# CM85F register map
Registers are read-write, no defined reset value unless marked. A register's access mark holds for its fields unless they carry their own. Offsets are from the block's base; lines under a group give offsets from that group; [hi:lo] are bit positions; {n}, {i} and the like mark numbered series; 'fields as' and 'values as' point back to an identical list; <NAME> marks a mode.

## Memory map
0xE0005000 RAS_Ext size 0x9F08 — Reliability, Availability, and Serviceability (RAS) Extension
0xE000E004 ICB size 0xC — Implementation Control Block
0xE000E100 NVIC size 0xF00 — Nested Vectored Interrupt Controller
0xE000ECFC SCB size 0x90 — System Control Block
0xE000EF34 FP_MVE size 0x18 — Floating-point and MVE Extension
0xE001E000 MSC size 0x19D00 — Memory System Control Registers
0xE001E100 ERRBNK size 0x8 — Implementation defined error banking
0xE001E200 DCA size 0x10 — Direct Cache Access

## NVIC — Nested Vectored Interrupt Controller
Base 0xE000E100
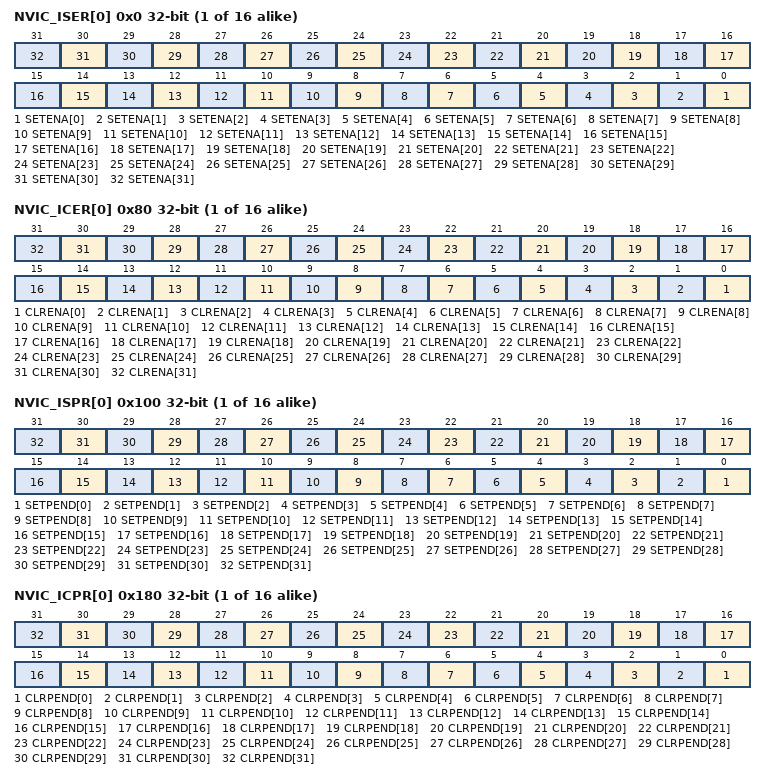
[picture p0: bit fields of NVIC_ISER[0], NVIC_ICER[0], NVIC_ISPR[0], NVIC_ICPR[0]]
{0x0+4i} NVIC_ISER[{i}] (i=0..15) — Interrupt Set Enable Register enables or reads the enabled state of each group of 32 interrupts
  [n] SETENA[{n}] (n=0..31) — Interrupt set-enable bits. For SETENA[m] in NVIC_ISERn, allows interrupt 32n+m to be accessed.
    0=On reads, interrupt disabled; 1=On reads, interrupt enabled
{0x80+4i} NVIC_ICER[{i}] (i=0..15) — Interrupt Clear Enable Register disables or reads the enable state of a group of interrupts
  [n] CLRENA[{n}] (n=0..31) — Interrupt clear-enable bits. For SETENA[m] in NVIC_ICERn, allows interrupt 32n+m to be accessed.
    values as NVIC_ISER[0].SETENA[0]
{0x100+4i} NVIC_ISPR[{i}] (i=0..15) — Interrupt Set Pending Register changes status to pending, or shows the current pending status for a group of interrupts
  [n] SETPEND[{n}] (n=0..31) — Interrupt set-pending bits. For SETPEND[m] in NVIC_ISPRn, allows interrupt 32n + m to be accessed.
    0=On reads, interrupt is not pending; 1=On reads, interrupt is pending
{0x180+4i} NVIC_ICPR[{i}] (i=0..15) — Interrupt Clear Pending Register clears the pending status, or shows the current pending status for a group of interrupts
  [n] CLRPEND[{n}] (n=0..31) — Interrupt clear-pending bits. Clears the pending state of interrupt (m+(32*n)), or shows whether the state of the interrupt is pending
    0=On reads, interrupt is not pending; 1=On reads, interrupt is pending; on writes, clear pending state
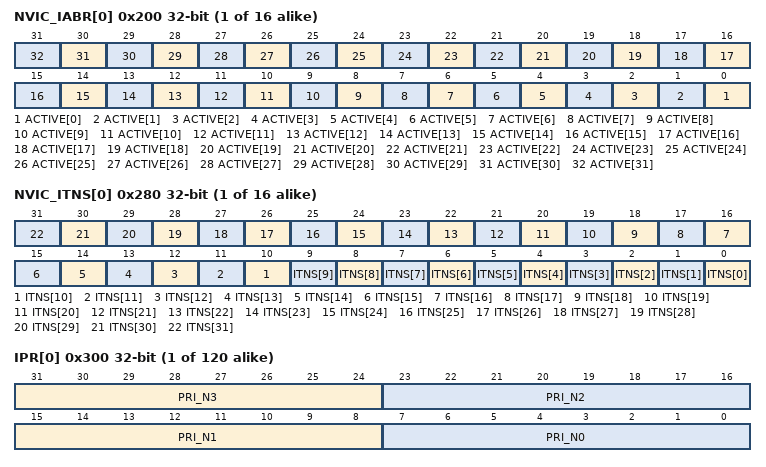
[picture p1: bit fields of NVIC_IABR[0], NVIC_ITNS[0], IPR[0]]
{0x200+4i} NVIC_IABR[{i}] (i=0..15) ro — Interrupt Active Bit Register shows whether each interrupt is active for a group of 32 interrupts
  [n] ACTIVE[{n}] (n=0..31) — For ACTIVE[m] in NVIC_IABRn, indicates the active state for interrupt 32n+m.
    0=Interrupt not active; 1=Interrupt active
{0x280+4i} NVIC_ITNS[{i}] (i=0..15) — Interrupt Targete Non-Secure Register specifies or reads whether each interrupt targets non-secure or secure state for a group of interrupts
  [n] ITNS[{n}] (n=0..31) — For ITNS[m] in NVIC_ITNSn, this field indicates and allows modification of the target Security state for interrupt 32n+m.
    0=Interrupt targets secure state; 1=Interrupt targets non-secure state
{0x300+4i} IPR[{i}] (i=0..119) — Interrupt Priority Register sets or reads interrupt priorities
  [31:24] PRI_N3 — For register NVIC_IPRn, priority of interrupt number 4n+3
  [23:16] PRI_N2 — For register NVIC_IPRn, priority of interrupt number 4n+2
  [15:8] PRI_N1 — For register NVIC_IPRn, priority of interrupt number 4n+1
  [7:0] PRI_N0 — For register NVIC_IPRn, priority of interrupt number 4n
0xE00 STIR wo — Software Trigger Interrupt Register write to the STIR to generate an interrupt from software.
  [8:0] INTID — Interrupt ID of the interrupt to trigger, in the range 0-479.

## ICB — Implementation Control Block
Base 0xE000E004
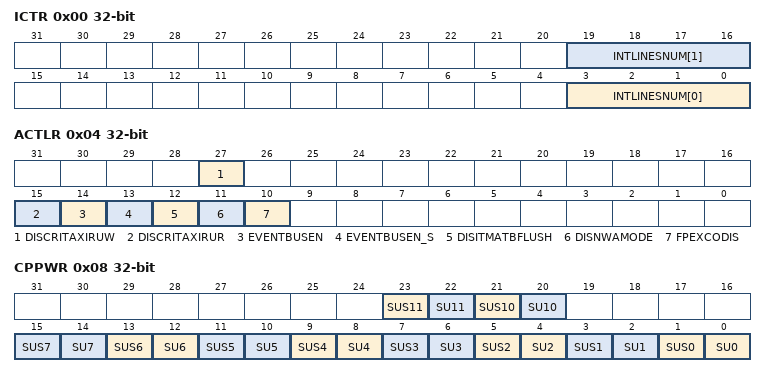
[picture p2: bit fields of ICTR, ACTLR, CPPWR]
0x00 ICTR ro — Interrupt Controller Type Register provides information about the interrupt controller
  [16n+3:16n] INTLINESNUM[{n}] (n=0..1) — The total number of interrupt lines supported by an implementation, defined in groups of 32
0x04 ACTLR — Auxiliary Control Register allow software to control the processor features and functionality
  [27] DISCRITAXIRUW — Disable-Critical-AXI-Read-Under-Write
    0=Normal operation; 1=AXI reads to Device memory and exclusive reads to shared memory are not initiated on the M-AXI read address channel until all outstanding writes on the M- AXI interface are complete
  [15] DISCRITAXIRUR — Disable critical AXI Read-Under-Read
    0=Normal operation; 1=AXI reads to Device memory and exclusive reads to shared memory are not initiated on the M-AXI read address channels if there are any outstanding reads on the M-AXI
  [14] EVENTBUSEN — Activate EVENTBUS output
    0=EVENTBUSEN is accessible by both Security states; 1=EVENTBUSEN is accessible by Secure state only
  [13] EVENTBUSEN_S — Accessibility of EVENTBUSEN
    values as EVENTBUSEN
  [12] DISITMATBFLUSH — Determines whether Instrumentation Trace Macrocell (ITM) or Data Watchpoint and Trace (DWT) ATB flush is disabled
    0=Normal operation; 1=ITM or DWT ATB flush is disabled
  [11] DISNWAMODE — Determines whether no write allocate mode is disabled
    0=Normal operation; 1=No write allocate mode is disabled
  [10] FPEXCODIS — Determines whether floating-point exception outputs are disabled
    0=Normal operation; 1=Floating-point exception outputs are disabled
0x08 CPPWR — Coprocessor Power Control Register specifies whether coprocessors are permitted to enter a non-retentive power state
  [23] SUS11 — If the value of this bit is not programmed to the same value as the SUS10 field, then the value is unknown.
  [22] SU11 — If the value of this bit is not programmed to the same value as the SU10 field, then the value is unknown.
  [21] SUS10 — This bit indicates and allows modification of whether the SU10 field can be modified from Non-secure state.
    0=The SU10 field is accessible from both Security states; 1=The SU10 field is only accessible from the Secure state
  [20] SU10 — This bit indicates and allows modification of whether the state associated with the floating-point and M-profile Vector Extension (MVE) functionality is permitted to become UNKNOWN.
    0=The floating-point and M-profile Vector Extension (MVE) state is not permitted to become unknown; 1=The floating-point and M-profile Vector Extension (MVE) state is permitted to become unknown
  [2n+1] SUS{n} (n=0..7) — This field indicates and allows modification of whether the SU{n} field can be modified from Non-secure state
    0=The SU{n} field is accessible from both Security states; 1=The SU{n} field is only accessible from the Secure state
  [2n] SU{n} (n=0..7) — This field indicates and allows modification of whether the state associated with coprocessor {n} is permitted to become unknown
    0=The coprocessor state is not permitted to become unknown; 1=The coprocessor state is permitted to become unknown
